# MK70F12 register map
Vendor: Freescale Semiconductor, Inc.; Series: Kinetis_K; File version: 1.6
CPU: CM4 r0p1, little endian, no MPU, FPU, VTOR, 4 interrupt priority bits
Registers are 32-bit, read-write, reset 0x0 unless marked. A register's access mark holds for its fields unless they carry their own. Offsets are from the block's base; [hi:lo] are bit positions.

## NFC — NAND flash controller
Base 0x400A8000; register names take the prefix NFC_
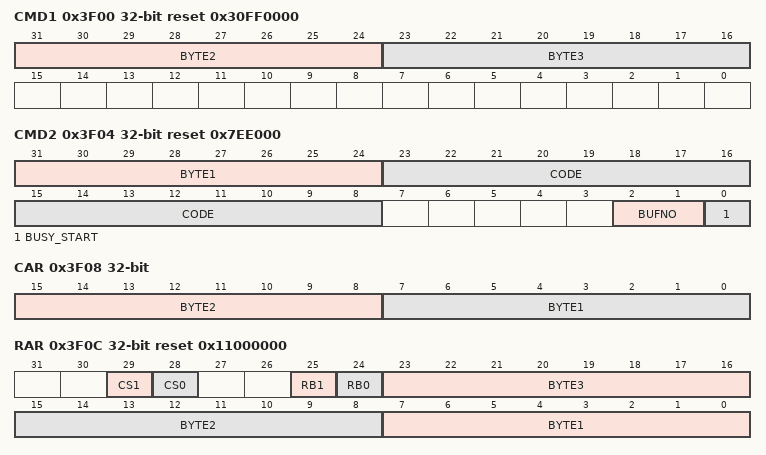
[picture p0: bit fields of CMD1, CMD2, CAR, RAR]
0x3F00 CMD1 reset 0x30FF0000 — Flash command 1
  [31:24] BYTE2 — Second command byte that may be sent to the flash device
  [23:16] BYTE3 — Third command byte that may be sent to the flash device
0x3F04 CMD2 reset 0x7EE000 — Flash command 2
  [31:24] BYTE1 — First command byte that may be sent to the flash device
  [23:8] CODE — User-defined flash operation sequencer
  [2:1] BUFNO — Internal buffer number used for this command
  [0] BUSY_START — Busy indicator and start command
    0=During reads, flash controller is idle and it is okay to send next command. During writes, no action.; 1=During reads, command execution is busy. During writes, start command execution.
0x3F08 CAR — Column address
  [15:8] BYTE2 — Second byte of column address
  [7:0] BYTE1 — First byte of column address
0x3F0C RAR reset 0x11000000 — Row address
  [29] CS1 — Chip select 1 enable
    0=NFC_CE1 is disabled; 1=NFC_CE1 is enabled
  [28] CS0 — Chip select 0 enable
    0=NFC_CE0 is disabled; 1=NFC_CE0 is enabled
  [25] RB1 — Ready/busy 1 enable
    0=NFC_R/ B 1 is disabled; 1=NFC_R/ B 1 is enabled
  [24] RB0 — Ready/busy 0 enable
    0=NFC_R/ B 0 is disabled; 1=NFC_R/ B 0 is enabled
  [23:16] BYTE3 — Third byte of row address
  [15:8] BYTE2 — Second byte of row address
  [7:0] BYTE1 — First byte of row address
0x3F10 RPT — Flash command repeat
  [15:0] COUNT — 16-bit repeat count
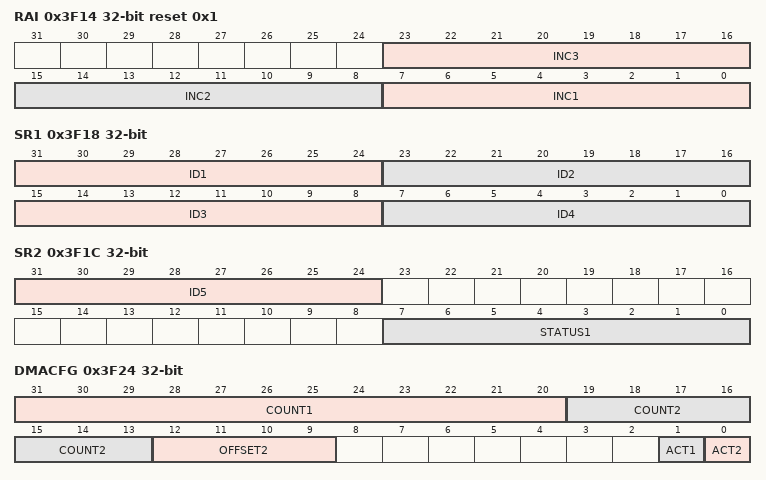
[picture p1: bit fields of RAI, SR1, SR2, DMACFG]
0x3F14 RAI reset 0x1 — Row address increment
  [23:16] INC3 — Increment for the third byte of row address
  [15:8] INC2 — Increment for the second byte of row address
  [7:0] INC1 — Increment for the first byte of row address
0x3F18 SR1 ro — Flash status 1
  [31:24] ID1 — First byte returned by read ID command
  [23:16] ID2 — Second byte returned by read ID command
  [15:8] ID3 — Third byte returned by read ID command
  [7:0] ID4 — Fourth byte returned by read ID command
0x3F1C SR2 ro — Flash status 2
  [31:24] ID5 — Fifth byte returned by read ID command
  [7:0] STATUS1 — Byte returned by read status command
0x3F20 DMA1 — DMA channel 1 address
  [31:0] ADDRESS — DMA channel 1 address. DMA channel 1 address, it is 8-byte aligned.
0x3F24 DMACFG — DMA configuration
  [31:20] COUNT1 — Number of bytes to be transferred by DMA channel 1. It should be multiple of 8 bytes.
  [19:13] COUNT2 — Number of bytes to be transferred by DMA channel 2. It should be multiple of 8 bytes.
  [12:9] OFFSET2 — 256-byte offset for DMA channel 2. DMA channel 2 transfer starts at this offset count x 256 bytes. For example, if OFFSET2 = 0x2, DMA channel 2 transfer starts at 0x200.
  [1] ACT1 — DMA channel 1 status
    0=Inactive; 1=Active, and transfers to memory when triggered
  [0] ACT2 — DMA channel 2 status
    0=Inactive; 1=Active, and transfers to memory when triggered
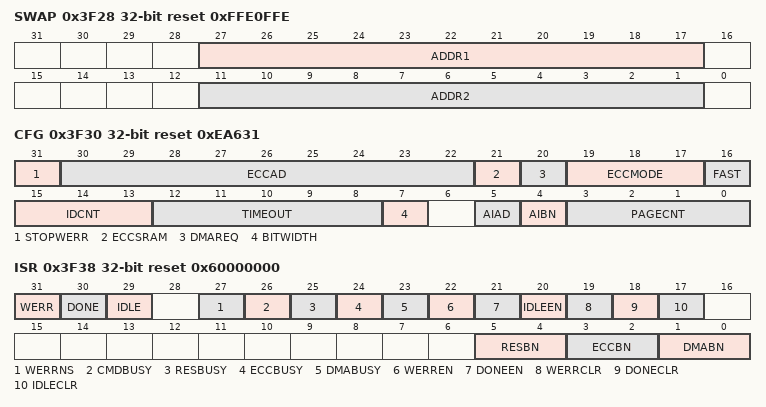
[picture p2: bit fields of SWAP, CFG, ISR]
0x3F28 SWAP reset 0xFFE0FFE — Cach swap
  [27:17] ADDR1 — Lower swap address
  [11:1] ADDR2 — Upper swap address
0x3F2C SECSZ reset 0x420 — Sector size
  [12:0] SIZE — Size in bytes of one elementary transfer unit
0x3F30 CFG reset 0xEA631 — Flash configuration
  [31] STOPWERR
    0=No stop on write error; 1=Auto-sequencer stops on a write error
  [30:22] ECCAD — Byte address in SRAM where ECC status is written.
  [21] ECCSRAM
    0=Do not write ECC status to SRAM; 1=Write ECC status to SRAM
  [20] DMAREQ
    0=Do not transfer sector after ECC done; 1=After ECC done, transfer sector using DMA
  [19:17] ECCMODE
    0=No correction, ECC bypass; 1=4-error correction (8 ECC bytes); 2=6-error correction (12 ECC bytes); 3=8-error correction (15 ECC bytes); 4=12-error correction (23 ECC bytes); 5=16-error correction (30 ECC bytes); 6=24-error correction (45 ECC bytes); 7=32-error correction (60 ECC bytes)
  [16] FAST — See the "Fast Flash Configuration for EDO" section for more details.
    0=Slow flash timing. Clock in read data on rising edge of read strobe; 1=Fast flash timing. Clock in read data a half clock later than rising edge of read strobe
  [15:13] IDCNT — Number of bytes that are read for the read id command.
  [12:8] TIMEOUT — The number of flash_clk cycles from NFC_WE high to either: NAND flash busy (t WB ), or NFC_RE low (t WHR ) After the last command is issued to flash, before sampling NFC_R/ B , the NFC must wait t WB clocks
  [7] BITWIDTH
    0=8-bit wide flash mode; 1=16-bit wide flash mode
  [5] AIAD
    0=Do not auto-increment flash row address; 1=Auto-increment flash row address
  [4] AIBN
    0=Do not auto-increment buffer number; 1=Auto-increment buffer number
  [3:0] PAGECNT — Number of virtual pages (in one physical flash page) to be programmed or read, etc.
0x3F34 DMA2 — DMA channel 2 address
  [31:0] ADDRESS — DMA channel 2 address. DMA channel 2 address, it is 8-byte aligned.
0x3F38 ISR reset 0x60000000 — Interrupt status
  [31] WERR ro — Write error interrupt
  [30] DONE ro — Done interrupt
  [29] IDLE ro — Command idle interrupt
  [27] WERRNS ro — Write error status
  [26] CMDBUSY ro — Command busy
  [25] RESBUSY ro — Residue engine busy
  [24] ECCBUSY ro — ECC engine busy
  [23] DMABUSY ro — DMA engine busy
  [22] WERREN — Enable bit for NFC_ISR[WERR]
  [21] DONEEN — Enable bit for NFC_ISR[DONE]
  [20] IDLEEN — Enable bit for NFC_ISR[IDLE]
  [19] WERRCLR — Clear bit for NFC_ISR[WERR]. Writing 1 to this bit clears NFC_ISR[WERR].
  [18] DONECLR — Clear bit for NFC_ISR[DONE]. Writing 1 to this bit clears NFC_ISR[DONE].
  [17] IDLECLR — Clear bit for NFC_ISR[IDLE]. Writing 1 to this bit clears NFC_ISR[IDLE].
  [5:4] RESBN ro — Residue buffer number
  [3:2] ECCBN ro — ECC buffer number
  [1:0] DMABN ro — DMA buffer number
